# C2000_VCU_Type2_Registers register map
Vendor: Texas Instruments
Peripheral module from a debugger description file (folder C2000).
Address unit: 16 bits
Registers are 16-bit, access not given, no defined reset value unless marked. A register's access mark holds for its fields unless they carry their own. Offsets are as the file gives them; lines under a group give offsets from that group; [hi:lo] are bit positions; {n}, {i} and the like mark numbered series; 'fields as' and 'values as' point back to an identical list; <NAME> marks a mode.

## VCU — VCU Registers
{0x0+2i} VR{i} 32-bit (i=0..8) — General Purpose 32-bit registers
0x12 VT0 32-bit — Transition Bit register
0x14 VT1 32-bit — Transition Bit register
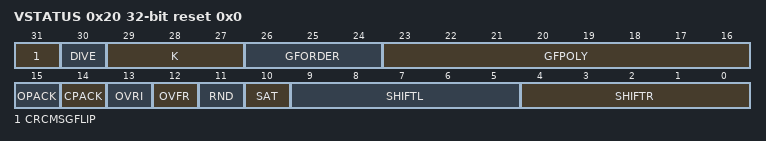
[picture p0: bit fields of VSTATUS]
0x20 VSTATUS 32-bit rw reset 0x0 — VCU Status Register
  [31] CRCMSGFLIP — CRC message flip
  [30] DIVE — Divide by zero error
  [29:27] K — Viterbi constraint length
  [26:24] GFORDER — Galois Field Polynomial Order
  [23:16] GFPOLY — Galois Field Polynomial
  [15] OPACK — Packing order of traceback bits
  [14] CPACK — Packing order[L:H]
  [13] OVRI — Imaginary party CMPY overflow
  [12] OVFR — General case overflow
  [11] RND — Rounding
  [10] SAT — Saturation
  [9:5] SHIFTL — Left shift modifier
  [4:0] SHIFTR — Right shift modifier
0x22 VCRC 32-bit — CRC Result register for un-secured memories
0x40 VCUREV 32-bit
{0x50+i} VSM{i} (i=0..63) — Viterbi Decoding State Metric register
{0xB0+8i} VR{i}_B0 32-bit (i=0..7)
{0xB2+8i} VR{i}_B1 32-bit (i=0..7)
{0xB4+8i} VR{i}_B2 32-bit (i=0..7)
{0xB6+8i} VR{i}_B3 32-bit (i=0..7)
